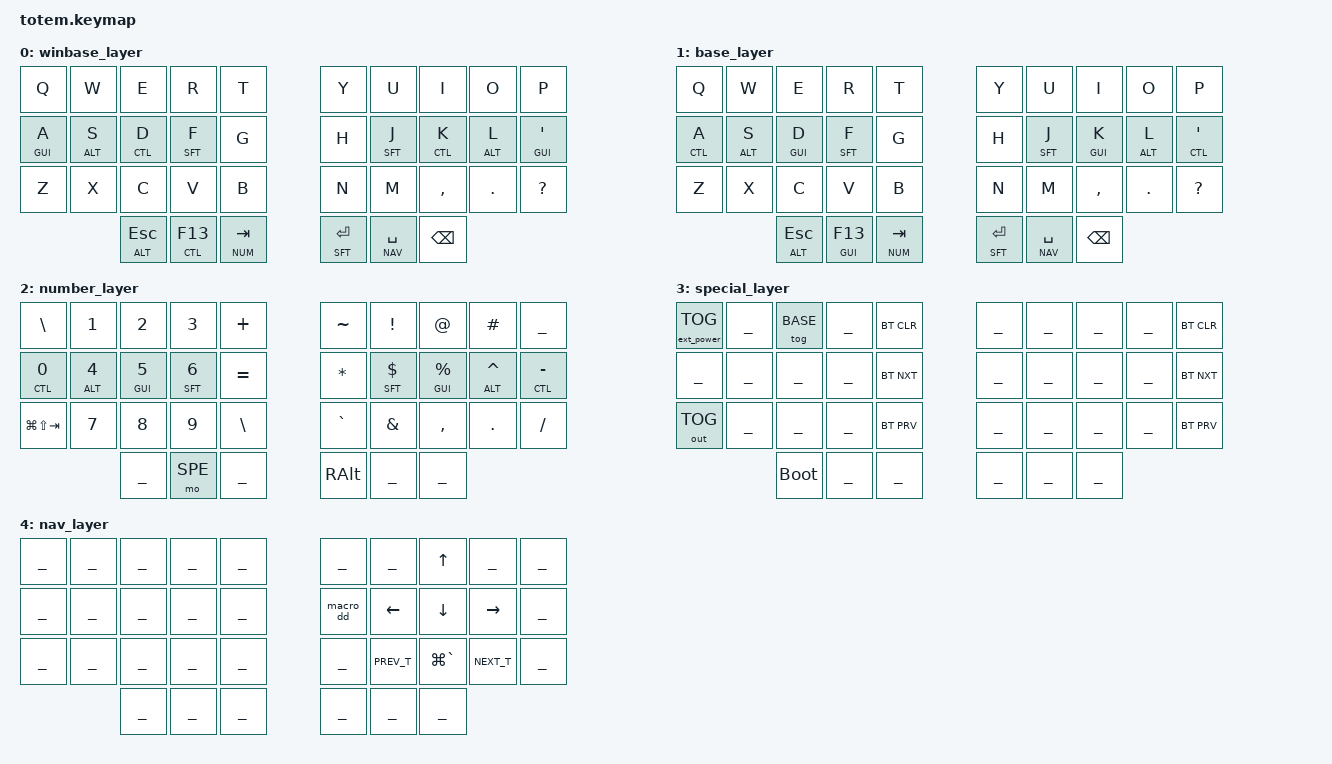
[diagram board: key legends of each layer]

#include <behaviors.dtsi>
#include <behaviors/num_word.dtsi>
#include "keypos_def/keypos_36keys_totem.h"     // keyposition helpers (Totem 36-key)
#include <dt-bindings/zmk/keys.h>
#include <dt-bindings/zmk/bt.h>
#include <dt-bindings/zmk/outputs.h>
#include <dt-bindings/zmk/ext_power.h>
#include "includes/defines.dtsi"
#include "includes/homerow_mods.dtsi"
#include "includes/settings.dtsi"
#include "includes/combos.dtsi"

/ {
    macros {
        macro_dd: macro_dd {
            compatible = "zmk,behavior-macro";
            #binding-cells = <0>;

            bindings
                = <&macro_press   &kp LCTRL>
                , <&macro_tap     &kp A &kp K &kp D>
                , <&macro_release &kp LCTRL>
                ;
        };
    };

    keymap {
        compatible = "zmk,keymap";

        winbase_layer {
            bindings = <
//╭─────────────┬─────────────┬─────────────┬─────────────┬─────────────╮         ╭─────────────┬─────────────┬─────────────┬─────────────┬─────────────╮
   &kp Q         &kp W         &kp E         &kp R         &kp T                   &kp Y         &kp U         &kp I         &kp O         &kp P
//├─────────────┼─────────────┼─────────────┼─────────────┼─────────────┤         ├─────────────┼─────────────┼─────────────┼─────────────┼─────────────┤
   &hml GUI A    &hml ALT S    &hml CTL D    &hmsl SFT F   &kp G                   &kp H         &hmsr SFT J   &hmsr CTL K   &hmr ALT L    &hmr GUI SQT
//├─────────────┼─────────────┼─────────────┼─────────────┼─────────────┤         ├─────────────┼─────────────┼─────────────┼─────────────┼─────────────┤
   &kp Z         &kp X         &kp C         &kp V         &kp B                   &kp N         &kp M         &kp COMMA     &kp DOT       &kp QMARK
//╰─────────────┼─────────────┼─────────────┼─────────────┼─────────────┤         ├─────────────┼─────────────┼─────────────┼─────────────┼─────────────╯
                               &mt ALT ESC   &mt CTL F13   &lt NUM TAB             &mt SFT RET   &lt NAV SPC   &kp BSPC
//                            ╰─────────────┴─────────────┴─────────────╯         ╰─────────────┴─────────────┴─────────────╯
            >;
        };

        base_layer {
            bindings = <
//╭─────────────┬─────────────┬─────────────┬─────────────┬─────────────╮         ╭─────────────┬─────────────┬─────────────┬─────────────┬─────────────╮
   &kp Q         &kp W         &kp E         &kp R         &kp T                   &kp Y         &kp U         &kp I         &kp O         &kp P
//├─────────────┼─────────────┼─────────────┼─────────────┼─────────────┤         ├─────────────┼─────────────┼─────────────┼─────────────┼─────────────┤
   &hml CTL A    &hml ALT S    &hml GUI D    &hmsl SFT F   &kp G                   &kp H         &hmsr SFT J   &hmr GUI K    &hmr ALT L    &hmr CTL SQT
//├─────────────┼─────────────┼─────────────┼─────────────┼─────────────┤         ├─────────────┼─────────────┼─────────────┼─────────────┼─────────────┤
   &kp Z         &kp X         &kp C         &kp V         &kp B                   &kp N         &kp M         &kp COMMA     &kp DOT       &kp QMARK
//╰─────────────┼─────────────┼─────────────┼─────────────┼─────────────┤         ├─────────────┼─────────────┼─────────────┼─────────────┼─────────────╯
                               &mt ALT ESC   &mt GUI F13   &lt NUM TAB             &mt SFT RET   &lt NAV SPC   &kp BSPC
//                            ╰─────────────┴─────────────┴─────────────╯         ╰─────────────┴─────────────┴─────────────╯
            >;
        };

        number_layer {
            bindings = <
//╭─────────────┬─────────────┬─────────────┬─────────────┬─────────────╮         ╭─────────────┬─────────────┬─────────────┬─────────────┬─────────────╮
   &kp BSLH      &kp N1        &kp N2        &kp N3        &kp PLUS                &kp TILDE     &kp EXCL      &kp AT        &kp HASH      &kp UNDER
//├─────────────┼─────────────┼─────────────┼─────────────┼─────────────┤         ├─────────────┼─────────────┼─────────────┼─────────────┼─────────────┤
   &hml CTL N0   &hml ALT N4   &hml GUI N5   &hmsl SFT N6  &kp EQUAL               &kp ASTRK   &hmsr SFT DLLR &hmr GUI PRCNT &hmr ALT CARET &hmr CTL MINUS
//├─────────────┼─────────────┼─────────────┼─────────────┼─────────────┤         ├─────────────┼─────────────┼─────────────┼─────────────┼─────────────┤
   &kp LG(LS(TAB)) &kp N7      &kp N8        &kp N9        &kp BSLH                &kp GRAVE     &kp AMPS      &kp COMMA     &kp DOT       &kp FSLH
//╰─────────────┼─────────────┼─────────────┼─────────────┼─────────────┤         ├─────────────┼─────────────┼─────────────┼─────────────┼─────────────╯
                               ___           &mo SPE       ___                     &kp RALT      ___           ___
//                            ╰─────────────┴─────────────┴─────────────╯         ╰─────────────┴─────────────┴─────────────╯
            >;
        };

        special_layer {
            bindings = <
//╭─────────────┬─────────────┬─────────────┬─────────────┬─────────────╮         ╭─────────────┬─────────────┬─────────────┬─────────────┬─────────────╮
&ext_power EP_TOG ___          &tog BASE     ___           &bt BT_CLR              ___           ___           ___           ___           &bt BT_CLR
//├─────────────┼─────────────┼─────────────┼─────────────┼─────────────┤         ├─────────────┼─────────────┼─────────────┼─────────────┼─────────────┤
   ___           ___           ___           ___           &bt BT_NXT              ___           ___           ___           ___           &bt BT_NXT
//├─────────────┼─────────────┼─────────────┼─────────────┼─────────────┤         ├─────────────┼─────────────┼─────────────┼─────────────┼─────────────┤
  &out OUT_TOG   ___           ___           ___           &bt BT_PRV              ___           ___           ___           ___           &bt BT_PRV
//╰─────────────┼─────────────┼─────────────┼─────────────┼─────────────┤         ├─────────────┼─────────────┼─────────────┼─────────────┼─────────────╯
                               &bootloader   ___           ___                     ___           ___           ___
//                            ╰─────────────┴─────────────┴─────────────╯         ╰─────────────┴─────────────┴─────────────╯
            >;
        };

        nav_layer {
            bindings = <
//╭─────────────┬─────────────┬─────────────┬─────────────┬─────────────╮         ╭─────────────┬─────────────┬─────────────┬─────────────┬─────────────╮
   ___           ___           ___           ___           ___                     ___           ___           &kp UP        ___           ___
//├─────────────┼─────────────┼─────────────┼─────────────┼─────────────┤         ├─────────────┼─────────────┼─────────────┼─────────────┼─────────────┤
   ___           ___           ___           ___           ___                     &macro_dd     &kp LEFT      &kp DOWN      &kp RIGHT     ___
//├─────────────┼─────────────┼─────────────┼─────────────┼─────────────┤         ├─────────────┼─────────────┼─────────────┼─────────────┼─────────────┤
   ___           ___           ___           ___           ___                     ___           &kp PREV_T    &kp LG(GRAVE) &kp NEXT_T    ___
//╰─────────────┼─────────────┼─────────────┼─────────────┼─────────────┤         ├─────────────┼─────────────┼─────────────┼─────────────┼─────────────╯
                               ___           ___           ___                     ___           ___           ___
//                            ╰─────────────┴─────────────┴─────────────╯         ╰─────────────┴─────────────┴─────────────╯
            >;
        };

    };


};
